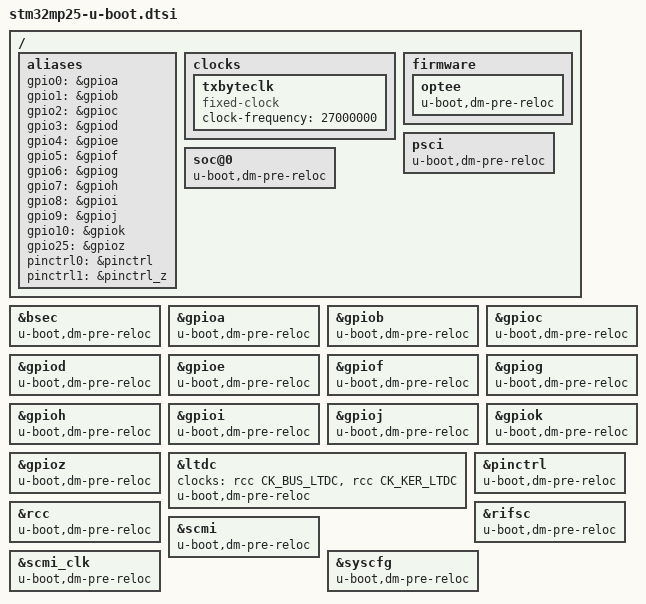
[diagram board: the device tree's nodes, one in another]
// SPDX-License-Identifier: GPL-2.0-or-later OR BSD-3-Clause
/*
 * Copyright : STMicroelectronics 2019
 */

/ {
	aliases {
		gpio0 = &gpioa;
		gpio1 = &gpiob;
		gpio2 = &gpioc;
		gpio3 = &gpiod;
		gpio4 = &gpioe;
		gpio5 = &gpiof;
		gpio6 = &gpiog;
		gpio7 = &gpioh;
		gpio8 = &gpioi;
		gpio9 = &gpioj;
		gpio10 = &gpiok;
		gpio25 = &gpioz;
		pinctrl0 = &pinctrl;
		pinctrl1 = &pinctrl_z;
	};

	clocks {
		txbyteclk {
			#clock-cells = <0>;
			compatible = "fixed-clock";
			clock-frequency = <27000000>;
		};
	};

	firmware {
		optee {
			u-boot,dm-pre-reloc;
		};
	};

	/* need PSCI for sysreset during board_f */
	psci {
		u-boot,dm-pre-reloc;
	};

	soc@0 {
		u-boot,dm-pre-reloc;
	};
};

&bsec {
	u-boot,dm-pre-reloc;
};

&gpioa {
	u-boot,dm-pre-reloc;
};

&gpiob {
	u-boot,dm-pre-reloc;
};

&gpioc {
	u-boot,dm-pre-reloc;
};

&gpiod {
	u-boot,dm-pre-reloc;
};

&gpioe {
	u-boot,dm-pre-reloc;
};

&gpiof {
	u-boot,dm-pre-reloc;
};

&gpiog {
	u-boot,dm-pre-reloc;
};

&gpioh {
	u-boot,dm-pre-reloc;
};

&gpioi {
	u-boot,dm-pre-reloc;
};

&gpioj {
	u-boot,dm-pre-reloc;
};

&gpiok {
	u-boot,dm-pre-reloc;
};

&gpioz {
	u-boot,dm-pre-reloc;
};

/* pre-reloc probe = reserve video frame buffer in video_reserve() */
&ltdc {
	clocks = <&rcc CK_BUS_LTDC>, <&rcc CK_KER_LTDC>;
	clock-names = "bus", "lcd";
	u-boot,dm-pre-reloc;
};

&pinctrl {
	u-boot,dm-pre-reloc;
};

&rcc {
	u-boot,dm-pre-reloc;
};

&rifsc {
	u-boot,dm-pre-reloc;
};

&scmi {
	u-boot,dm-pre-reloc;
};

&scmi_clk {
	u-boot,dm-pre-reloc;
};

&syscfg {
	u-boot,dm-pre-reloc;
};
